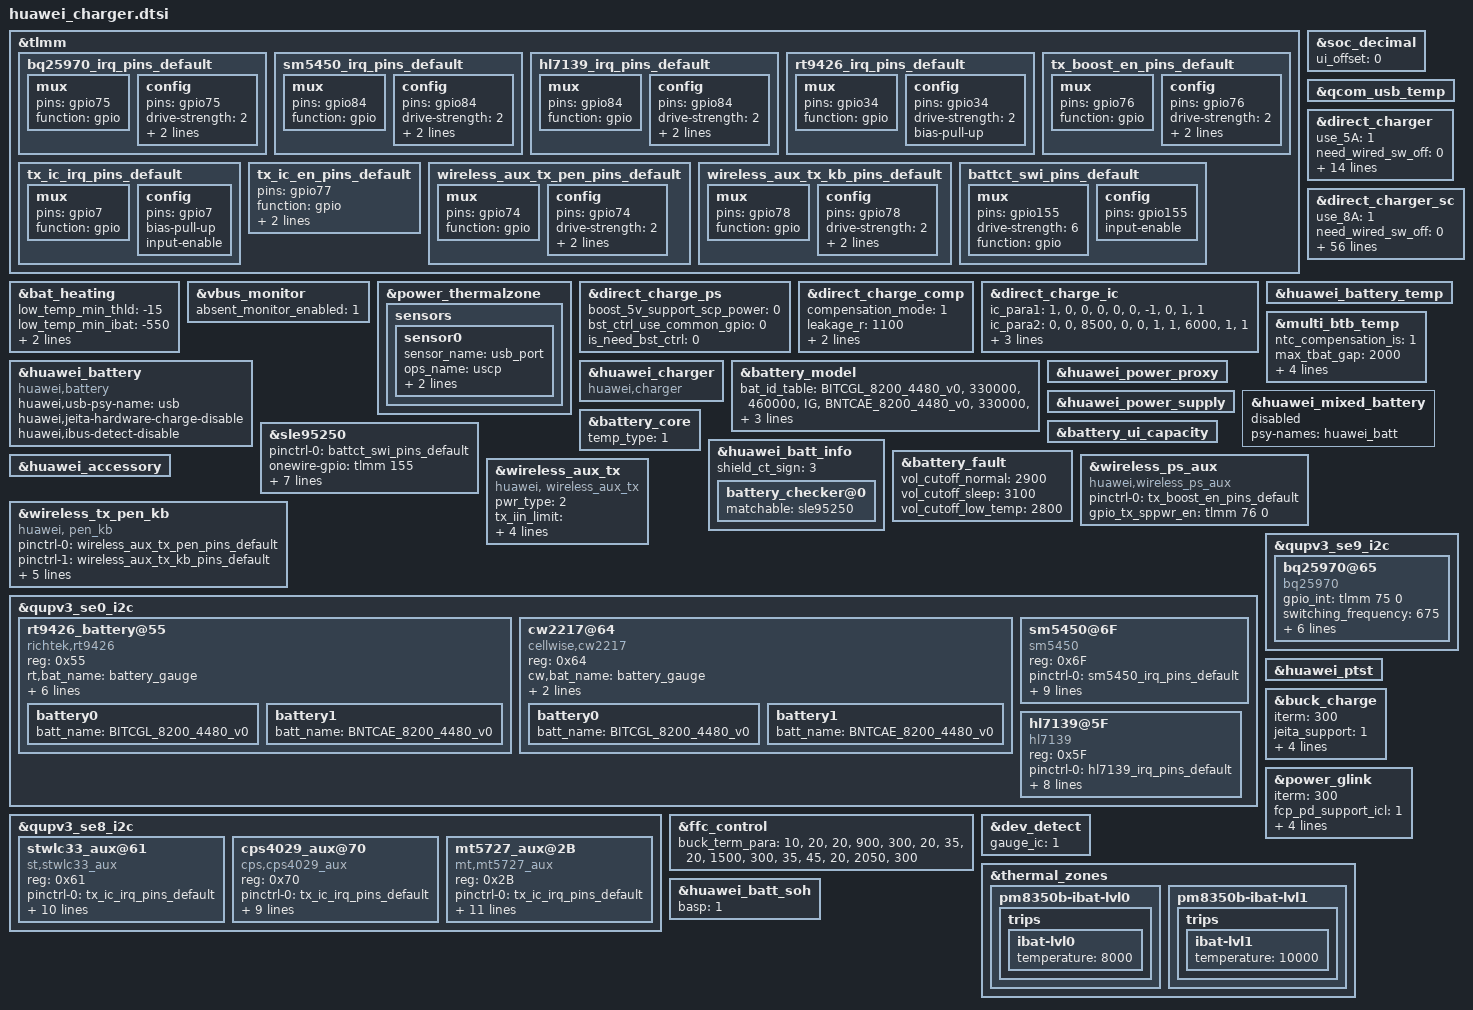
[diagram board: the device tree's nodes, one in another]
&tlmm {
	bq25970_irq_pins_default: bq25970_irq_pins_default {
		mux {
			pins = "gpio75";
			function = "gpio";
		};
		config {
			pins = "gpio75";
			drive-strength = <2>;
			bias-pull-up;
			input-enable;
		};
	};

	sm5450_irq_pins_default: sm5450_irq_pins_default {
		mux {
			pins = "gpio84";
			function = "gpio";
		};
		config {
			pins = "gpio84";
			drive-strength = <2>;
			bias-pull-up;
			input-enable;
		};
	};

	hl7139_irq_pins_default: hl7139_irq_pins_default {
		mux {
			pins = "gpio84";
			function = "gpio";
		};
		config {
			pins = "gpio84";
			drive-strength = <2>;
			bias-pull-up;
			input-enable;
		};
	};

	rt9426_irq_pins_default: rt9426_irq_pins_default {
		mux {
			pins = "gpio34";
			function = "gpio";
		};
		config {
			pins = "gpio34";
			drive-strength = <2>;
			bias-pull-up;
		};
	};

	tx_boost_en_pins_default: tx_boost_en_pins_default {
		mux {
			pins = "gpio76";
			function = "gpio";
		};
		config {
			pins = "gpio76";
			drive-strength = <2>;
			bias-pull-down;
			input-enable;
		};
	};

	tx_ic_irq_pins_default: tx_ic_irq_pins_default {
		mux {
			pins = "gpio7";
			function = "gpio";
		};
		config {
			pins = "gpio7";
			bias-pull-up;
			input-enable;
		};
	};

	tx_ic_en_pins_default: tx_ic_en_pins_default {
		pins = "gpio77";
		function = "gpio";
		output-high;
		bias-pull-up;
	};

	wireless_aux_tx_pen_pins_default: wireless_aux_tx_pen_pins_default {
		mux {
			pins = "gpio74";
			function = "gpio";
		};
		config {
			pins = "gpio74";
			drive-strength = <2>;
			bias-pull-up;
			input-enable;
		};
	};

	wireless_aux_tx_kb_pins_default: wireless_aux_tx_kb_pins_default {
		mux {
			pins = "gpio78";
			function = "gpio";
		};
		config {
			pins = "gpio78";
			drive-strength = <2>;
			bias-pull-down;
			input-enable;
		};
	};

	battct_swi_pins_default: battct_swi_pins_default {
		mux {
			pins = "gpio155";
			drive-strength = <6>;
			function = "gpio";
		};
		config {
			pins = "gpio155";
			input-enable;
		};
	};
};

&bat_heating {
	low_temp_min_thld = "-15";
	low_temp_min_ibat = "-550";
	temp_para =
		"-32767", "0", "0",
		"0", "5", "0",
		"5", "10", "400",
		"10", "20", "2500",
		"20", "45", "4500",
		"45", "32767", "0";
	status = "ok";
};

&soc_decimal {
	ui_offset = <0>;
	status = "ok";
};

&vbus_monitor {
	status = "ok";
	absent_monitor_enabled = <1>;
};

&power_thermalzone {
	status = "ok";
	sensors{
		sensor0 {
			sensor_name = "usb_port";
			ops_name = "uscp";
			adc_channel = <0>;
			ntc_index = <5>;
		};
	};
};

&qcom_usb_temp {
	status = "ok";
};

&direct_charge_ps {
	boost_5v_support_scp_power = <0>;
	bst_ctrl_use_common_gpio = <0>;
	is_need_bst_ctrl = <0>;
	status = "ok";
};

&direct_charge_comp {
	compensation_mode = <1>;
	leakage_r = <1100>;
	compensate_r = <5>;
	/* The vbat_samp_point_para table is used to find the comp relationship between chips */
	/* Calculate all compensation values of the same index */
	/* as the final compensation of the chip */
	/* Separately calculate positive and negative poles */
	/* ic_index  p_index  n_index */
	vbat_samp_point_para =
		"0", "0", "0",
		"1", "1", "0";
	status = "ok";
};

&direct_charge_ic {
	/* The IC_PARA table is used to find the relationship between chip and path */
	/* the chip's current passing capacity */
	/* and the sampling points of battery voltage and current */
	/* ic_index  path_index  max_ibat  ibat_sample_point  vbat_sample_point */
	ic_para1 =
		"1", "0", "0", "0", "0",
		"0", "-1", "0", "1", "1";
	ic_para2 =
		"0", "0", "8500", "0", "0",
		"1", "1", "6000", "1", "1";
	mode_para =
		"lvc_mode", "ic_para1",
		"sc_mode", "ic_para2";
	use_coul_ibat = <1>;
	status = "ok";
};

&direct_charger {
	use_5A = <1>;
	need_wired_sw_off = <0>;
	volt_para =
		"4080", "5000", "4650",
		"4230", "4650", "2800",
		"4400", "2800", "1200";
	vbat_comp_para =
		"default", "50", "0";
	compensate_r = <0>;
	cc_cable_detect_enable = <1>;
	full_path_res_max = <220>;
	scp_work_on_charger = <1>;
	standard_cable_full_path_res_max = <330>;
	first_cc_stage_timer_in_min = <5>;
	stage_need_to_jump = "1";
	low_temp_hysteresis = <5>;
	temp_para =
		"-32767", "10", "0",
		"10", "45", "5000",
		"45", "32767", "0";
	rt_test_para =
		"2000", "105"; /* rt_curr_th rt_test_time */
	status = "ok";
};

&direct_charger_sc {
	use_8A = <1>;
	need_wired_sw_off = <0>;
	dc_volt_ratio = <2>;
	init_delt_vset = <450>;
	max_adaptor_vset = <11000>;
	init_adapter_vset = <8800>;
	vol_err_th = <500>;
	adaptor_leakage_current_th = <300>;
	vstep = <20>;
	min_dc_bat_vol = <3450>;
	max_dc_bat_vol = <4380>;
	max_current_for_none_standard_cable = <6000>;
	adaptor_antifake_check_enable = <1>;
	adaptor_antifake_key_index = <2>;
	support_multi_ic = <1>;
	multi_ic_ibat_th = <7600>;
	second_resist_check_en = <1>;
	ui_max_pwr = <40000>;
	product_max_pwr = <66000>;
	delta_err_10v2p25a = <150>;
	is_show_ico_first = <1>;
	volt_para =
		"4350", "9840", "8200",
		"4480", "8200", "5740",
		"4490", "5740", "1600";
	volt_para1 =
		"4350", "12000", "9840",
		"4480", "9840", "8200",
		"4490", "8200", "1600";
	volt_para2 =
		"4350", "12000", "9840",
		"4480", "9840", "8200",
		"4490", "8200", "2050";
	time_para =
		"300", "10000",
		"60", "11000";
	bat_para =
		"default", "10", "20", "volt_para",
		"default", "20", "35", "volt_para1",
		"default", "35", "45", "volt_para2",
		"CAE", "10", "20", "volt_para",
		"CAE", "20", "35", "volt_para1",
		"CAE", "35", "45", "volt_para2",
		"CGL", "10", "20", "volt_para",
		"CGL", "20", "35", "volt_para1",
		"CGL", "35", "45", "volt_para2";
	vbat_comp_para =
		"default", "45", "0",
		"bq25970", "44", "19",
		"rt9759", "44", "34";
	vstep_para =
		"2000", "80";
	compensate_r = <0>;
	cc_cable_detect_enable = <1>;
	full_path_res_max = <450>;
	scp_work_on_charger = <1>;
	standard_cable_full_path_res_max = <450>;
	first_cc_stage_timer_in_min = <14>;
	stage_need_to_jump = "-1";
	low_temp_hysteresis = <5>;
	current_ratio =
		"3", "10", "25", "2", "-1",
		"3", "12", "23", "1", "8000",
		"0", "12", "23", "0", "0";
	vbat_error =
		"3", "120", "2", "-1",
		"3", "80", "1", "0";
	temp_para =
		"-32767", "10", "0",
		"10", "20", "12000",
		"20", "45", "12800",
		"45", "32767", "0";
	resist_para =
		"0", "260", "6000",
		"260", "450", "4000";
	std_resist_para =
		"0", "300", "0",
		"300", "450", "12000";
	second_resist_para =
		"0", "180", "0",
		"180", "450", "12000";
	ctc_second_resist_para =
		"0", "250", "0",
		"250", "450", "12000";
	rt_test_para =
		/* first:sc second:mainsc third:auxsc */
		"3000", "105",
		"3000", "105",
		"3000", "105";
	adapter_max_power_time_para =
		"3", "0", "7200",
		"7", "0", "7200",
		"8", "0", "7200",
		"17", "0", "7200",
		"19", "0", "7200";
	status = "ok";
};

&huawei_battery_temp {
	status = "ok";
};

&multi_btb_temp {
	status = "ok";
	ntc_compensation_is = <1>;
	max_tbat_gap = <2000>;
	comp_para =
		"11000", "30000",
		"10000", "25000",
		"9000", "20000",
		"8000", "15000",
		"7000", "12000",
		"6000", "8000",
		"5000", "6000",
		"3000", "3000",
		"2000", "2000";
	sensor-names =
		"battery_gauge", "comp_para";
};

&huawei_battery {
	compatible = "huawei,battery";
	status = "ok";
	huawei,usb-psy-name = "usb";
	huawei,jeita-hardware-charge-disable;
	huawei,ibus-detect-disable;
};

&huawei_charger {
	compatible = "huawei,charger";
	status = "ok";
};

&battery_model {
	bat_id_table =
		"BITCGL_8200_4480_v0", "330000", "460000", "IG",
		"BNTCAE_8200_4480_v0", "330000", "460000", "NA";
	design_fcc = <8200>;
	id_adc_channel = <0>; /* useless but necessary for Qcom, set 0 as default */
	status = "ok";
};

&huawei_power_proxy {
	status = "ok";
};

&huawei_power_supply {
	 status = "ok";
};

&huawei_mixed_battery {
	psy-names = "huawei_batt";
	status = "disabled";
};

&battery_core {
	temp_type = <1>;
	status = "ok";
};

&battery_ui_capacity {
	status = "ok";
};

&sle95250 {
	pinctrl-names = "default";
	pinctrl-0 = <&battct_swi_pins_default>;
	onewire-gpio = <&tlmm 155 0>;
	product_id0 = <1>;
	product_id2 = <3>;
	dip_check = <0>;
	gpio_swi = <155>;
	gpio_swi_drv = <2>;
	tau = /bits/ 8 <0xa>;
	tau_fastboot = <7>;
	status = "ok";
};

&huawei_batt_info {
	status = "ok";
	shield_ct_sign = <3>;
	battery_checker@0 {
		matchable = <&sle95250>;
		status = "ok";
	};
};

&battery_fault {
	vol_cutoff_normal = <2900>;
	vol_cutoff_sleep = <3100>;
	vol_cutoff_low_temp = <2800>;
	status = "ok";
};

&huawei_accessory {
	status = "ok";
};

&wireless_ps_aux {
	compatible = "huawei,wireless_ps_aux";
	pinctrl-names = "default";
	pinctrl-0 = <&tx_boost_en_pins_default>;
	gpio_tx_sppwr_en = <&tlmm 76 0>;
	status = "ok";
};

&wireless_aux_tx {
	compatible = "huawei, wireless_aux_tx";
	pwr_type = <2>; /* 0:VBUS_OTG 1:5VBST_OTG 2:SP-BST */
	tx_iin_limit = <0 500 300 1000 1000 0 0 0 0 1000 0 0>;
	iin_vset_para = <
		0   520   4850
		550 20000 5500
	>;
	ping_timeout_1 = <2>;
	ping_timeout_2 = <7>;
	status = "ok";
};

&wireless_tx_pen_kb {
	compatible = "huawei, pen_kb";
	pinctrl-names = "default", "default";
	pinctrl-0 = <&wireless_aux_tx_pen_pins_default>;
	pinctrl-1 = <&wireless_aux_tx_kb_pins_default>;
	gpio_tx_pen_en = <&tlmm 74 0>;
	gpio_tx_kb_en = <&tlmm 78 0>;
	support_pen_kb_switch = <1>;
	ping_timeout_pen = <2>;
	ping_timeout_kb = <30>;
	status = "ok";
};

&qupv3_se0_i2c {
	#address-cells = <1>;
	#size-cells = <0>;
	status = "ok";
	rt9426_battery@55{
		reg = <0x55>;
		compatible = "richtek,rt9426";
		rt,bat_name = "battery_gauge";
		pinctrl-names = "default";
		pinctrl-0 = <&rt9426_irq_pins_default>;
		rt9426,gpio-intb = <&tlmm 34 0x0>;
		need_reset_version = <9>;
		rt_config_ver = <18>;
		ground_loop_comp_en = <1>;
		ground_loop_comp_rcomp = <41>;
		status = "ok";
		battery0{
			batt_name = "BITCGL_8200_4480_v0";
			#include "../../../huawei_charger/rt9426_BITCGL_8200mAh_4V48_GOT_BT243.dtsi"
		};
		battery1{
			batt_name = "BNTCAE_8200_4480_v0";
			#include "../../../huawei_charger/rt9426_BNTCAE_8200mAh_4V48_GOT_BT243.dtsi"
		};
	};

	cw2217@64 {
		compatible = "cellwise,cw2217";
		reg = <0x64>;
		cw,bat_name = "battery_gauge";
		ground_loop_comp_en = <1>;
		ground_loop_comp_rcomp = <41>;
		status = "ok";
		battery0{
			batt_name = "BITCGL_8200_4480_v0";
			#include "../../../huawei_charger/cw2217_1mohm_BITCGL_8200mAh_4V48_GOT_BT243.dtsi"
		};
		battery1{
			batt_name = "BNTCAE_8200_4480_v0";
			#include "../../../huawei_charger/cw2217_1mohm_BNTCAE_8200mAh_4V48_GOT_BT243.dtsi"
		};
	};

	sm5450@6F{
		compatible = "sm5450";
		reg = <0x6F>;
		pinctrl-names = "default";
		pinctrl-0 = <&sm5450_irq_pins_default>;
		intr_gpio_num = <84>; /* direct defined GPIO num */
		intr_gpio = <&tlmm 84 0>;
		fcp_support = <1>;
		scp_support = <1>;
		sense_r_actual = <15>;
		sense_r_config = <10>;
		close_regulation = <1>;
		vdp_no_check = <1>;
		ic_role = <1>;
		status = "ok";
	};

	hl7139@5F {
		compatible = "hl7139";
		reg = <0x5F>;
		pinctrl-names = "default";
		pinctrl-0 = <&hl7139_irq_pins_default>;
		intr_gpio = <&tlmm 84 0>;
		sense_r_actual = <15>;
		sense_r_config = <10>;
		fcp_support = <1>;
		scp_support = <1>;
		switching_frequency = <500>;
		ic_role = <1>;
		vbat_ovp_para = <5000>;
		status = "ok";
	};
};

&qupv3_se8_i2c {
	#address-cells = <1>;
	#size-cells = <0>;
	status = "ok";
	stwlc33_aux@61 {
		compatible = "st,stwlc33_aux";
		reg = <0x61>;
		pinctrl-names = "default,default";
		pinctrl-0 = <&tx_ic_irq_pins_default>;
		pinctrl-1 = <&tx_ic_en_pins_default>;
		interrupt-parent = <&tlmm>;
		interrupts = <7 0>;
		gpio_int = <&tlmm 7 0>;
		gpio_en = <&tlmm 77 0>;
		gpio_en_valid_val = <0>;
		tx_fod_th_5v = <1500>;
		support_tx_adjust_vin = <1>;
		ping_freq_init_dym = <135>;
		tx_ploss_th0 = /bits/ 8 <33>; /* unit 100mW */
		status = "ok";
	};

	cps4029_aux@70 {
		compatible = "cps,cps4029_aux";
		reg = <0x70>;
		pinctrl-names = "default,default";
		pinctrl-0 = <&tx_ic_irq_pins_default>;
		pinctrl-1 = <&tx_ic_en_pins_default>;
		interrupt-parent = <&tlmm>;
		interrupts = <7 0>;
		gpio_int = <&tlmm 7 0>;
		gpio_en = <&tlmm 77 0>;
		tx_min_fop = <120>;
		tx_max_fop = <145>;
		tx_ploss_th0 = <3300>;
		tx_ploss_cnt = /bits/ 8 <5>;
		status = "ok";
	};

	mt5727_aux@2B {
		compatible = "mt,mt5727_aux";
		reg = <0x2B>;
		pinctrl-names = "default,default";
		pinctrl-0 = <&tx_ic_irq_pins_default>;
		pinctrl-1 = <&tx_ic_en_pins_default>;
		interrupt-parent = <&tlmm>;
		interrupts = <7 0>;
		gpio_int = <&tlmm 7 0>;
		gpio_en = <&tlmm 77 0>;
		gpio_en_valid_val = <0>;
		tx_ping_ocp_th = <900>;
		tx_min_fop = /bits/ 16 <120>;
		tx_max_fop = /bits/ 16 <145>;
		tx_ploss_th0 = /bits/ 16 <3300>;
		tx_ploss_cnt = /bits/ 16 <5>;
		status = "ok";
	};
};

&qupv3_se9_i2c {
	#address-cells = <1>;
	#size-cells = <0>;
	status = "ok";
	bq25970@65 {
		compatible = "bq25970";
		gpio_int = <&tlmm 75 0>;
		switching_frequency = <675>;
		reg = <0x65>;
		pinctrl-names = "default";
		pinctrl-0 = <&bq25970_irq_pins_default>;
		ic_role = <0>;
		sense_r_actual = <15>;
		sense_r_config = <20>;
		resume_need_wait_i2c = <1>;
		status = "ok";
	};
};

&huawei_ptst {
	status = "ok";
};

&buck_charge {
	iterm = <300>;
	jeita_support = <1>;
	jeita_table =
		"-32767", "0", "-1", "0", "4500", "0",
		"0", "5", "-1", "715", "4500", "0",
		"5", "10", "-1", "2145", "4500", "3",
		"10", "45", "-1", "3000", "4500", "3",
		"45", "50", "-1", "2502", "4100", "3",
		"50", "32767", "-1", "0", "4100", "0";
	status = "ok";
};

&power_glink {
	iterm = <300>;
	fcp_pd_support_icl = <1>;
	jeita_fv = <4480>;
	jeita_hot_th = <70>;
	adsp_jeita_table = <
		0 5 3000 4500
		5 10 3000 4500
		10 65 3000 4500
		65 70 3000 4100
	>;
};

&ffc_control {
	status = "ok";
	buck_term_para =
		"10", "20", "20", "900", "300",
		"20", "35", "20", "1500", "300",
		"35", "45", "20", "2050", "300";
};

&dev_detect {
	gauge_ic = <1>;
	status = "ok";
};

&thermal_zones {
	pm8350b-ibat-lvl0 {
		trips {
			ibat-lvl0 {
				temperature = <8000>;
			};
		};
	};

	pm8350b-ibat-lvl1 {
		trips {
			ibat-lvl1 {
				temperature = <10000>;
			};
		};
	};
};

&huawei_batt_soh {
	basp = <1>;
	status = "ok";
};
